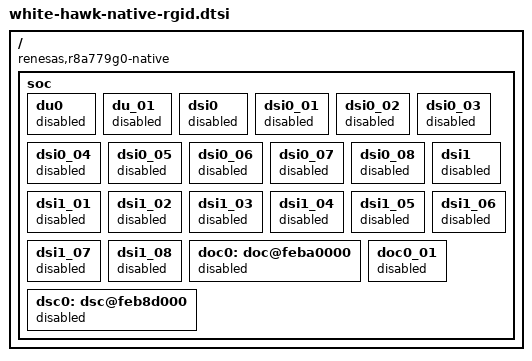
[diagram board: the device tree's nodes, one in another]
// SPDX-License-Identifier: (GPL-2.0-only OR BSD-2-Clause)
/*
 * Device Tree Source support Native RGID for the White Hawk CPU
 * boards with R-Car V4H
 *
 * Copyright (C) 2025 Renesas Electronics Corp.
 */

#include "r8a779g0-rgid.dtsi"

/ {
	compatible = "renesas,r8a779g0-native", "renesas,r8a779g0";

	soc: soc {
		du0 {
			status = "disabled";
		};

		du_01 {
			status = "disabled";
		};

		dsi0 {
			status = "disabled";
		};

		dsi0_01 {
			status = "disabled";
		};

		dsi0_02 {
			status = "disabled";
		};

		dsi0_03 {
			status = "disabled";
		};

		dsi0_04 {
			status = "disabled";
		};

		dsi0_05 {
			status = "disabled";
		};

		dsi0_06 {
			status = "disabled";
		};

		dsi0_07 {
			status = "disabled";
		};

		dsi0_08 {
			status = "disabled";
		};

		dsi1 {
			status = "disabled";
		};

		dsi1_01 {
			status = "disabled";
		};

		dsi1_02 {
			status = "disabled";
		};

		dsi1_03 {
			status = "disabled";
		};

		dsi1_04 {
			status = "disabled";
		};

		dsi1_05 {
			status = "disabled";
		};

		dsi1_06 {
			status = "disabled";
		};

		dsi1_07 {
			status = "disabled";
		};

		dsi1_08 {
			status = "disabled";
		};

		doc0: doc@feba0000 {
			status = "disabled";
		};

		doc0_01 {
			status = "disabled";
		};

		dsc0: dsc@feb8d000 {
			status = "disabled";
		};
	};
};
